# TM4C123BH6ZRB register map
Vendor: Texas Instruments; Series: TM4C; File version: 12591
CPU: CM4 r1p2, little endian, MPU, FPU, 3 interrupt priority bits
Registers are 32-bit, read-write, no defined reset value unless marked. A register's access mark holds for its fields unless they carry their own. Offsets are from the block's base; [hi:lo] are bit positions.

## SYSEXC — Register map for SYSEXC peripheral
Base 0x400F9000; register names take the prefix SYSEXC
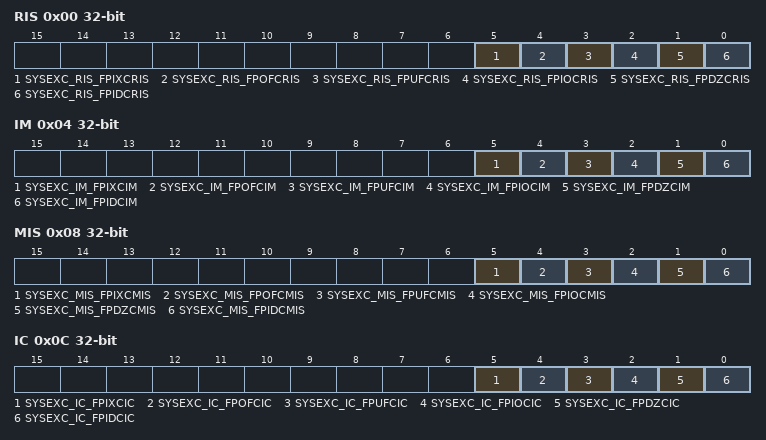
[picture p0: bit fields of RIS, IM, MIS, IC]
0x00 RIS — System Exception Raw Interrupt Status
  [5] SYSEXC_RIS_FPIXCRIS — Floating-Point Inexact Exception Raw Interrupt Status
  [4] SYSEXC_RIS_FPOFCRIS — Floating-Point Overflow Exception Raw Interrupt Status
  [3] SYSEXC_RIS_FPUFCRIS — Floating-Point Underflow Exception Raw Interrupt Status
  [2] SYSEXC_RIS_FPIOCRIS — Floating-Point Invalid Operation Raw Interrupt Status
  [1] SYSEXC_RIS_FPDZCRIS — Floating-Point Divide By 0 Exception Raw Interrupt Status
  [0] SYSEXC_RIS_FPIDCRIS — Floating-Point Input Denormal Exception Raw Interrupt Status
0x04 IM — System Exception Interrupt Mask
  [5] SYSEXC_IM_FPIXCIM — Floating-Point Inexact Exception Interrupt Mask
  [4] SYSEXC_IM_FPOFCIM — Floating-Point Overflow Exception Interrupt Mask
  [3] SYSEXC_IM_FPUFCIM — Floating-Point Underflow Exception Interrupt Mask
  [2] SYSEXC_IM_FPIOCIM — Floating-Point Invalid Operation Interrupt Mask
  [1] SYSEXC_IM_FPDZCIM — Floating-Point Divide By 0 Exception Interrupt Mask
  [0] SYSEXC_IM_FPIDCIM — Floating-Point Input Denormal Exception Interrupt Mask
0x08 MIS — System Exception Masked Interrupt Status
  [5] SYSEXC_MIS_FPIXCMIS — Floating-Point Inexact Exception Masked Interrupt Status
  [4] SYSEXC_MIS_FPOFCMIS — Floating-Point Overflow Exception Masked Interrupt Status
  [3] SYSEXC_MIS_FPUFCMIS — Floating-Point Underflow Exception Masked Interrupt Status
  [2] SYSEXC_MIS_FPIOCMIS — Floating-Point Invalid Operation Masked Interrupt Status
  [1] SYSEXC_MIS_FPDZCMIS — Floating-Point Divide By 0 Exception Masked Interrupt Status
  [0] SYSEXC_MIS_FPIDCMIS — Floating-Point Input Denormal Exception Masked Interrupt Status
0x0C IC wo — System Exception Interrupt Clear
  [5] SYSEXC_IC_FPIXCIC — Floating-Point Inexact Exception Interrupt Clear
  [4] SYSEXC_IC_FPOFCIC — Floating-Point Overflow Exception Interrupt Clear
  [3] SYSEXC_IC_FPUFCIC — Floating-Point Underflow Exception Interrupt Clear
  [2] SYSEXC_IC_FPIOCIC — Floating-Point Invalid Operation Interrupt Clear
  [1] SYSEXC_IC_FPDZCIC — Floating-Point Divide By 0 Exception Interrupt Clear
  [0] SYSEXC_IC_FPIDCIC — Floating-Point Input Denormal Exception Interrupt Clear

## HIB — Register map for HIB peripheral
Base 0x400FC000; register names take the prefix HIB
0x00 RTCC — Hibernation RTC Counter
  [31:0] HIB_RTCC — RTC Counter
0x04 RTCM0 — Hibernation RTC Match 0
  [31:0] HIB_RTCM0 — RTC Match 0
0x0C RTCLD — Hibernation RTC Load
  [31:0] HIB_RTCLD — RTC Load
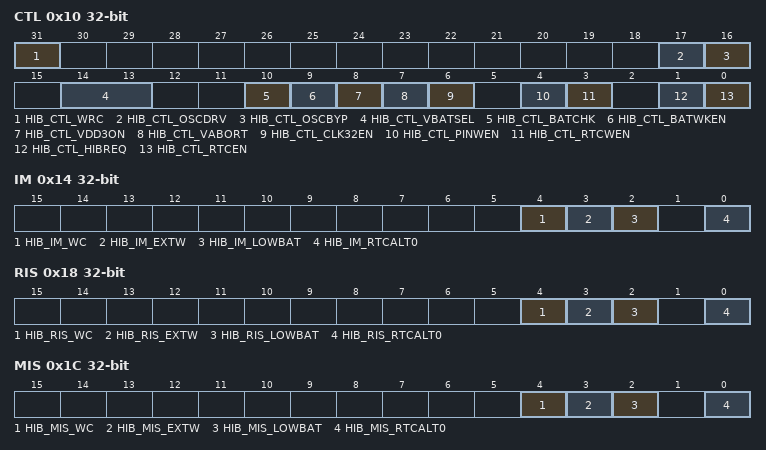
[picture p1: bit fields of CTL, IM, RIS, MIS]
0x10 CTL — Hibernation Control
  [31] HIB_CTL_WRC — Write Complete/Capable
  [17] HIB_CTL_OSCDRV — Oscillator Drive Capability
  [16] HIB_CTL_OSCBYP — Oscillator Bypass
  [14:13] HIB_CTL_VBATSEL — Select for Low-Battery Comparator
    0=HIB_CTL_VBATSEL_1_9V (1.9 Volts); 1=HIB_CTL_VBATSEL_2_1V (2.1 Volts (default)); 2=HIB_CTL_VBATSEL_2_3V (2.3 Volts); 3=HIB_CTL_VBATSEL_2_5V (2.5 Volts)
  [10] HIB_CTL_BATCHK — Check Battery Status
  [9] HIB_CTL_BATWKEN — Wake on Low Battery
  [8] HIB_CTL_VDD3ON — VDD Powered
  [7] HIB_CTL_VABORT — Power Cut Abort Enable
  [6] HIB_CTL_CLK32EN — Clocking Enable
  [4] HIB_CTL_PINWEN — External Wake Pin Enable
  [3] HIB_CTL_RTCWEN — RTC Wake-up Enable
  [1] HIB_CTL_HIBREQ — Hibernation Request
  [0] HIB_CTL_RTCEN — RTC Timer Enable
0x14 IM — Hibernation Interrupt Mask
  [4] HIB_IM_WC — External Write Complete/Capable Interrupt Mask
  [3] HIB_IM_EXTW — External Wake-Up Interrupt Mask
  [2] HIB_IM_LOWBAT — Low Battery Voltage Interrupt Mask
  [0] HIB_IM_RTCALT0 — RTC Alert 0 Interrupt Mask
0x18 RIS — Hibernation Raw Interrupt Status
  [4] HIB_RIS_WC — Write Complete/Capable Raw Interrupt Status
  [3] HIB_RIS_EXTW — External Wake-Up Raw Interrupt Status
  [2] HIB_RIS_LOWBAT — Low Battery Voltage Raw Interrupt Status
  [0] HIB_RIS_RTCALT0 — RTC Alert 0 Raw Interrupt Status
0x1C MIS — Hibernation Masked Interrupt Status
  [4] HIB_MIS_WC — Write Complete/Capable Masked Interrupt Status
  [3] HIB_MIS_EXTW — External Wake-Up Masked Interrupt Status
  [2] HIB_MIS_LOWBAT — Low Battery Voltage Masked Interrupt Status
  [0] HIB_MIS_RTCALT0 — RTC Alert 0 Masked Interrupt Status
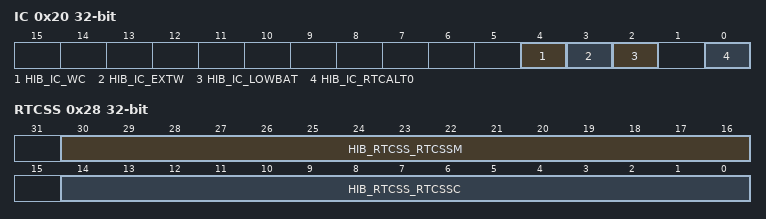
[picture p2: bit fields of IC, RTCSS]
0x20 IC — Hibernation Interrupt Clear
  [4] HIB_IC_WC — Write Complete/Capable Interrupt Clear
  [3] HIB_IC_EXTW — External Wake-Up Interrupt Clear
  [2] HIB_IC_LOWBAT — Low Battery Voltage Interrupt Clear
  [0] HIB_IC_RTCALT0 — RTC Alert0 Masked Interrupt Clear
0x24 RTCT — Hibernation RTC Trim
  [15:0] HIB_RTCT_TRIM — RTC Trim Value
0x28 RTCSS — Hibernation RTC Sub Seconds
  [30:16] HIB_RTCSS_RTCSSM — RTC Sub Seconds Match
  [14:0] HIB_RTCSS_RTCSSC — RTC Sub Seconds Count
0x30 DATA — Hibernation Data
  [31:0] HIB_DATA_RTD — Hibernation Module NV Data

## Notices in the file
Software License Agreement
Texas Instruments (TI) is supplying this software for use solely and
exclusively on TI's microcontroller products. The software is owned by
TI and/or its suppliers, and is protected under applicable copyright
laws. You may not combine this software with "viral" open-source
software in order to form a larger program.
THIS SOFTWARE IS PROVIDED "AS IS" AND WITH ALL FAULTS.
NO WARRANTIES, WHETHER EXPRESS, IMPLIED OR STATUTORY, INCLUDING, BUT
NOT LIMITED TO, IMPLIED WARRANTIES OF MERCHANTABILITY AND FITNESS FOR
A PARTICULAR PURPOSE APPLY TO THIS SOFTWARE. TI SHALL NOT, UNDER ANY
CIRCUMSTANCES, BE LIABLE FOR SPECIAL, INCIDENTAL, OR CONSEQUENTIAL
DAMAGES, FOR ANY REASON WHATSOEVER.
